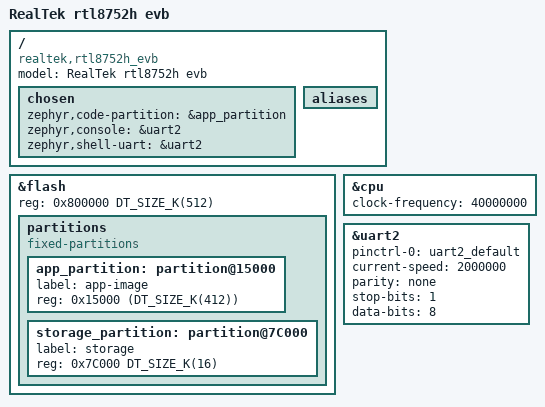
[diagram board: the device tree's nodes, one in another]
/dts-v1/;
#include <realtek/rtl8752h.dtsi>
#include "rtl8752htv_evb-pinctrl.dtsi"

/ {
	model = "RealTek rtl8752h evb ";
	compatible = "realtek,rtl8752h_evb";

	chosen {
		zephyr,code-partition = &app_partition;
		zephyr,console = &uart2;
		zephyr,shell-uart = &uart2;
	};

	/* These aliases are provided for compatibility with samples */
	aliases {
	};

};

&flash {
	reg = <0x800000 DT_SIZE_K(512)>;
	partitions {
		compatible = "fixed-partitions";
		#address-cells = <1>;
		#size-cells = <1>;
		app_partition: partition@15000 {
			label = "app-image";
			reg = <0x15000 (DT_SIZE_K(412))>;
		};
		storage_partition: partition@7C000 {
			label = "storage";
			reg = <0x7C000 DT_SIZE_K(16)>;
		};
	};
};

&cpu {
	clock-frequency = <40000000>;
};

&uart2 {
	pinctrl-0 = <&uart2_default>;
	pinctrl-names = "default";
	status = "okay";
	current-speed = <2000000>;
	parity = "none";
	stop-bits = "1";
	data-bits = <8>;
};
